# apollo3c register map
Vendor: Ambiq Micro; Series: Apollo; File version: 1.0
CPU: CM4 r1p0, little endian, MPU, FPU, 3 interrupt priority bits
Registers are 32-bit, read-write, reset 0x0 unless marked. A register's access mark holds for its fields unless they carry their own. Offsets are from the block's base; [hi:lo] are bit positions; {n}, {i} and the like mark numbered series; 'fields as' and 'values as' point back to an identical list.

## IOM0 — IO Peripheral Master
Base 0x50004000
Same registers: IOM1 0x50005000, IOM2 0x50006000, IOM3 0x50007000, IOM4 0x50008000, IOM5 0x50009000
0x00 FIFO — FIFO Access Port
  [31:0] FIFO — FIFO direct access. Only locations 0 - 3F will return valid information.
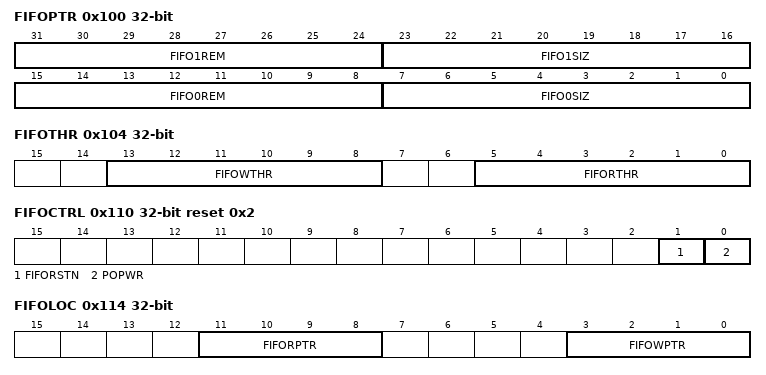
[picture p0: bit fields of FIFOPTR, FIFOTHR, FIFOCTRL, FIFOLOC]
0x100 FIFOPTR — FIFO size and remaining slots open values
  [31:24] FIFO1REM — The number of remaining data bytes slots currently in FIFO 1 (written by interface, read by MCU)
  [23:16] FIFO1SIZ — The number of valid data bytes currently in FIFO 1 (written by interface, read by MCU)
  [15:8] FIFO0REM — The number of remaining data bytes slots currently in FIFO 0 (written by MCU, read by interface)
  [7:0] FIFO0SIZ — The number of valid data bytes currently in the FIFO 0 (written by MCU, read by interface)
0x104 FIFOTHR — FIFO Threshold Configuration
  [13:8] FIFOWTHR — FIFO write threshold in bytes. A value of 0 will disable the write FIFO level from activating the threshold interrupt. If this field is non-zero, it will trigger a threshold interrupt when the write fifo contains FIFOWTHR free bytes, as indicated by the FIFO0REM field. This is intended to signal when a transfer of FIFOWTHR bytes can be done from the host to the IOM write fifo to support large IOM write operations.
  [5:0] FIFORTHR — FIFO read threshold in bytes. A value of 0 will disable the read FIFO level from activating the threshold interrupt. If this field is non-zero, it will trigger a threshold interrupt when the read fifo contains FIFORTHR valid bytes of data, as indicated by the FIFO1SIZ field. This is intended to signal when a data transfer of FIFORTHR bytes can be done from the IOM module to the host via the read fifo to support large IOM read operations.
0x108 FIFOPOP
  [31:0] FIFODOUT — This register will return the read data indicated by the current read pointer on reads. If the POPWR control bit in the FIFOCTRL register is reset (0), the fifo read pointer will be advanced by one word as a result of the read. If the POPWR bit is set (1), the fifo read pointer will only be advanced after a write operation to this register. The write data is ignored for this register. If less than a even word multiple is available, and the command is completed, the module will return the word containing these bytes and undetermined data in the unused fields of the word.
0x10C FIFOPUSH
  [31:0] FIFODIN — This register is used to write the FIFORAM in FIFO mode and will cause a push event to occur to the next open slot within the FIFORAM. Writing to this register will cause the write point to increment by 1 word(4 bytes).
0x110 FIFOCTRL reset 0x2 — FIFO Control Register
  [1] FIFORSTN — Active low manual reset of the fifo. Write to 0 to reset fifo, and then write to 1 to remove the reset.
  [0] POPWR — Selects the mode in which 'pop' events are done for the fifo read operations. A value of '1' will prevent a pop event on a read operation, and will require a write to the FIFOPOP register to create a pop event. A value of '0' in this register will allow a pop event to occur on the read of the FIFOPOP register, and may cause inadvertant fifo pops when used in a debugging mode.
0x114 FIFOLOC — FIFO Pointers
  [11:8] FIFORPTR — Current FIFO read pointer. Used to index into the incoming FIFO (FIFO1), which is used to store read data returned from external devices during a read operation.
  [3:0] FIFOWPTR — Current FIFO write pointer. Value is the index into the outgoing FIFO (FIFO0), which is used during write operations to external devices.
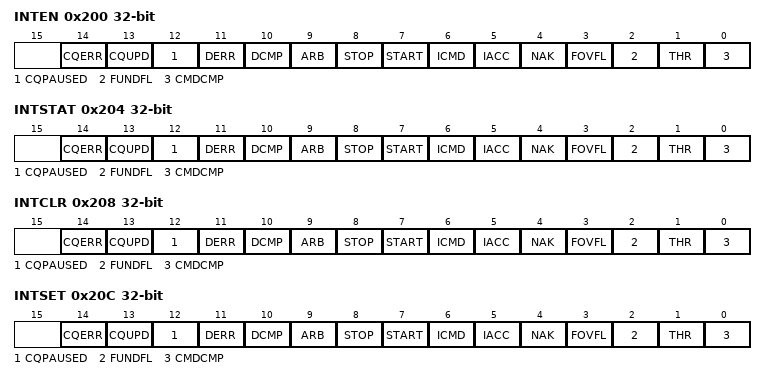
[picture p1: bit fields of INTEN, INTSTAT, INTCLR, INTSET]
0x200 INTEN — IO Master Interrupts: Enable
  [14] CQERR — Error during command queue operations
  [13] CQUPD — CQ write operation performed a register write with the register address bit 0 set to 1. The low address bits in the CQ address fields are unused and bit 0 can be used to trigger an interrupt to indicate when this register write is performed by the CQ operation.
  [12] CQPAUSED — Command queue is paused due to an active event enabled in the PAUSEEN register. The interrupt is posted when the event is enabled within the PAUSEEN register, the mask is active in the CQIRQMASK field and the event occurs.
  [11] DERR — DMA Error encountered during the processing of the DMA command. The DMA error could occur when the memory access specified in the DMA operation is not available or incorrectly specified.
  [10] DCMP — DMA Complete. Processing of the DMA operation has completed and the DMA submodule is returned into the idle state
  [9] ARB — Arbitration loss interrupt. Asserted when arbitration is enabled and has been lost to another master on the bus.
  [8] STOP — STOP command interrupt. Asserted when another master on the bus has signaled a STOP command.
  [7] START — START command interrupt. Asserted when another master on the bus has signaled a START command.
  [6] ICMD — illegal command interrupt. Asserted when a command is written when an active command is in progress.
  [5] IACC — illegal FIFO access interrupt. Asserted when there is a overflow or underflow event
  [4] NAK — I2C NAK interrupt. Asserted when an unexpected NAK has been received on the I2C bus.
  [3] FOVFL — Write FIFO Overflow interrupt. This occurs when software tries to write to a full fifo. The current operation does not stop.
  [2] FUNDFL — Read FIFO Underflow interrupt. This occurs when software tries to pop from an empty fifo.
  [1] THR — FIFO Threshold interrupt. For write operations, asserted when the number of free bytes in the write FIFO equals or exceeds the WTHR field. For read operations, asserted when the number of valid bytes in the read FIFO equals of exceeds the value set in the RTHR field.
  [0] CMDCMP — Command complete interrupt
0x204 INTSTAT — IO Master Interrupts: Status
  fields as INTEN
0x208 INTCLR — IO Master Interrupts: Clear
  fields as INTEN
0x20C INTSET — IO Master Interrupts: Set
  fields as INTEN
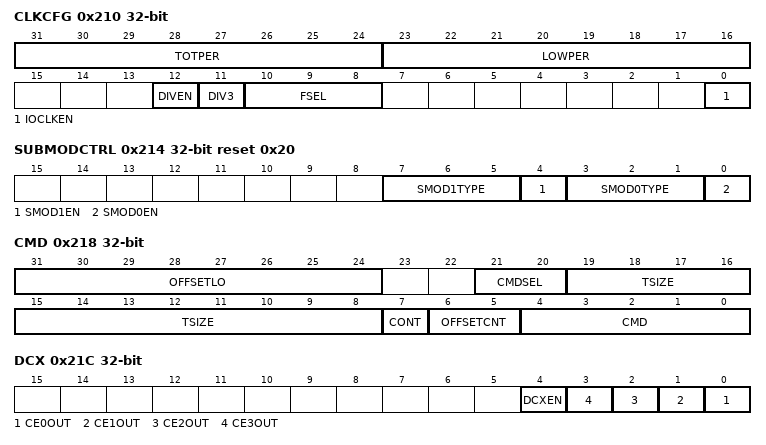
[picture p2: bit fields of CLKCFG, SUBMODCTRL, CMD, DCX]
0x210 CLKCFG — I/O Clock Configuration
  [31:24] TOTPER — Clock total clock count minus 1. This provides the total period of the divided clock -1 when the DIVEN is active. The source clock is selected by FSEL. Only applicable when DIVEN = 1.
  [23:16] LOWPER — Clock low clock count minus 1. This provides the number of clocks the divided clock will be low when the DIVEN = 1. Only applicable when DIVEN = 1.
  [12] DIVEN — Enable clock division by TOTPER and LOWPER
    0=DIS (Disable TOTPER division.); 1=EN (Enable TOTPER division.)
  [11] DIV3 — Enable divide by 3 of the source IOCLK. Division by 3 is done before the DIVEN programmable divider, and if enabled will provide the divided by 3 clock as the source to the programmable divider.
    0=DIS (Select divide by 1.); 1=EN (Select divide by 3.)
  [10:8] FSEL — Select the input clock frequency.
    0=MIN_PWR (Selects the minimum power clock. This setting should be used whenever the IOM is not active.); 1=HFRC (Selects the HFRC as the input clock.); 2=HFRC_DIV2 (Selects the HFRC / 2 as the input clock.); 3=HFRC_DIV4 (Selects the HFRC / 4 as the input clock.); 4=HFRC_DIV8 (Selects the HFRC / 8 as the input clock.); 5=HFRC_DIV16 (Selects the HFRC / 16 as the input clock.); 6=HFRC_DIV32 (Selects the HFRC / 32 as the input clock.); 7=HFRC_DIV64 (Selects the HFRC / 64 as the input clock.)
  [0] IOCLKEN — Enable for the interface clock. Must be enabled prior to executing any IO operations.
0x214 SUBMODCTRL reset 0x20 — Submodule control
  [7:5] SMOD1TYPE — Submodule 0 module type. This is the I2C Master interface
    0=MSPI (SPI Master submodule); 1=I2C_MASTER (MI2C submodule); 2=SSPI (SPI Slave submodule); 3=SI2C (I2C Slave submodule); 7=NA (NOT INSTALLED)
  [4] SMOD1EN — Submodule 1 enable (1) or disable (0)
  [3:1] SMOD0TYPE — Submodule 0 module type. This is the SPI Master interface.
    0=SPI_MASTER (MSPI submodule); 1=I2C_MASTER (I2C Master submodule); 2=SSPI (SPI Slave submodule); 3=SI2C (I2C Slave submodule); 7=NA (NOT INSTALLED)
  [0] SMOD0EN — Submodule 0 enable (1) or disable (0)
0x218 CMD — Command and offset Register
  [31:24] OFFSETLO — This register holds the low order byte of offset to be used in the transaction. The number of offset bytes to use is set with bits 1:0 of the command.
  [21:20] CMDSEL — Command Specific selection information. Not used in Master I2C. Used as CEn select for Master SPI transactions
  [19:8] TSIZE — Defines the transaction size in bytes. The offset transfer is not included in this size.
  [7] CONT — Contine to hold the bus after the current transaction if set to a 1 with a new command issued.
  [6:5] OFFSETCNT — Number of offset bytes to use for the command - 0, 1, 2, 3 are valid selections. The second (byte 1) and third byte (byte 2) are read from the OFFSETHI register, and the low order byte is pulled from this register in the OFFSETLO field. Offset bytes are transmitted highest byte first. EG if offsetcnt == 3, OFFSETHI[15:8] will be transmitted first, then OFFSETHI[7:0] then OFFSETLO. If offsetcnt == 2, OFFSETHI[7:0] will be transmitted, then OFFSETLO. If offsetcnt == 1, only OFFSETLO will be transmitted. Offset bytes are always transmitted MSB first, regardless of the value of the LSB control bit within the module configuration.
  [4:0] CMD — Command for submodule.
    1=WRITE (Write command using count of offset bytes specified in the OFFSETCNT field); 2=READ (Read command using count of offset bytes specified in the OFFSETCNT field); 3=TMW (SPI only. Test mode to do constant write operations. Useful for debug and power measurements. Will continually send data in OFFSET field); 4=TMR (SPI Only. Test mode to do constant read operations. Useful for debug and power measurements. Will continually read data from external input)
0x21C DCX — DCX Control Register
  [4] DCXEN — DCX Signaling Enable The selected DCX signal (unused CE pin) will be driven low during write of offset byte, and high during transmission of data bytes.
    16=EN (Enable DCX.); 0=DIS (Disable DCX.)
  [n] CE{n}OUT (n=0..3) — Enable DCX output using CE{n} output
0x220 OFFSETHI — High order 2 bytes of 3 byte offset for IO transaction
  [15:0] OFFSETHI — Holds the high order 2 bytes of the 3 byte addressing/offset field to use with IO commands. The number of offset bytes to use is specified in the command register
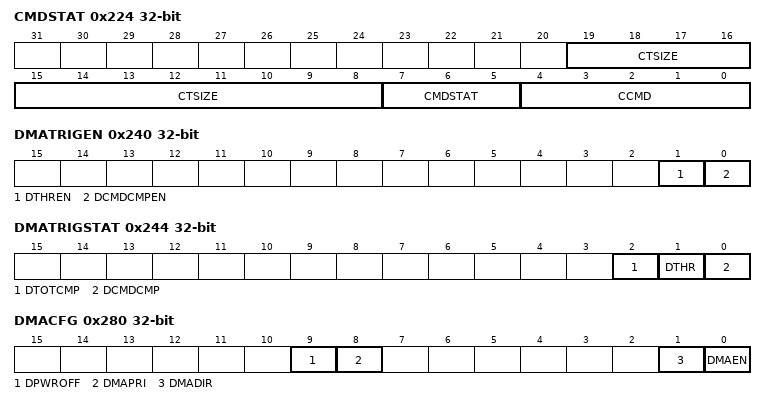
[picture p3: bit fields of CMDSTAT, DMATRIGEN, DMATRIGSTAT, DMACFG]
0x224 CMDSTAT — Command status
  [19:8] CTSIZE — The current number of bytes still to be transferred with this command. This field will count down to zero.
  [7:5] CMDSTAT — The current status of the command execution.
    1=ERR (Error encountered with command); 2=ACTIVE (Actively processing command); 4=IDLE (Idle state, no active command, no error); 6=WAIT (Command in progress, but waiting on data from host)
  [4:0] CCMD — current command that is being executed
0x240 DMATRIGEN — DMA Trigger Enable Register
  [1] DTHREN — Trigger DMA upon THR level reached. For M2P DMA operations (IOM writes), the trigger will assert when the write FIFO has (WTHR/4) number of words free in the write FIFO, and will transfer (WTHR/4) number of words or, if the number of words left to transfer is less than the WTHR value, will transfer the remaining byte count. For P2M DMA operations, the trigger will assert when the read FIFO has (RTHR/4) words available in the read FIFO, and will transfer (RTHR/4) words to SRAM. This trigger will NOT assert when the transaction completes and there are less than RTHR bytes left in the fifo, since the RTHR has not been reached. In this case, the CMDCMP trigger must also be enabled to transfer the remaining read FIFO data to SRAM.
  [0] DCMDCMPEN — Trigger DMA upon command complete. Enables the trigger of the DMA when a command is completed. When this event is triggered, the number of words transferred will be the lesser of the remaining TOTCOUNT bytes, or
0x244 DMATRIGSTAT — DMA Trigger Status Register
  [2] DTOTCMP — DMA triggered when DCMDCMP = 0, and the amount of data in the FIFO was enough to complete the DMA operation (greater than or equal to current TOTCOUNT) when the command completed. This trigger is default active when the DCMDCMP trigger is disabled and there is enough data in the FIFO to complete the DMA operation.
  [1] DTHR — Triggered DMA from THR event. Bit is read only and can be cleared by disabling the DTHR trigger enable or by disabling DMA.
  [0] DCMDCMP — Triggered DMA from Command complete event. Bit is read only and can be cleared by disabling the DCMDCMP trigger enable or by disabling DMA.
0x280 DMACFG — DMA Configuration Register
  [9] DPWROFF — Power off module after DMA is complete. If this bit is active, the module will request to power off the supply it is attached to. If there are other units still requiring power from the same domain, power down will not be performed.
    0=DIS (Power off disabled); 1=EN (Power off enabled)
  [8] DMAPRI — Sets the Priority of the DMA request
    0=LOW (Low Priority (service as best effort)); 1=HIGH (High Priority (service immediately))
  [1] DMADIR — Direction
    0=P2M (Peripheral to Memory (SRAM) transaction. To be set when doing IOM read operations, ie reading data from external devices.); 1=M2P (Memory to Peripheral transaction. To be set when doing IOM write operations, ie writing data to external devices.)
  [0] DMAEN — DMA Enable. Setting this bit to EN will start the DMA operation. This should be the last DMA related register set prior to issuing the command
    0=DIS (Disable DMA Function); 1=EN (Enable DMA Function)
0x288 DMATOTCOUNT — DMA Total Transfer Count
  [11:0] TOTCOUNT — Triggered DMA from Command complete event occured. Bit is read only and can be cleared by disabling the DTHR trigger enable or by disabling DMA.
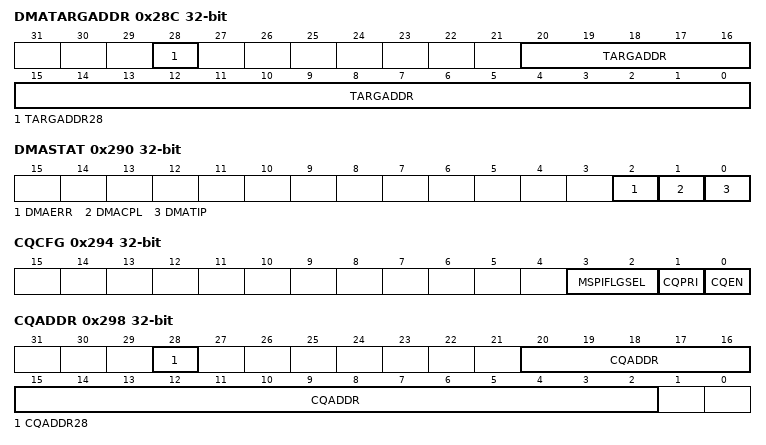
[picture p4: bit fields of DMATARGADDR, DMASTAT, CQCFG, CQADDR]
0x28C DMATARGADDR — DMA Target Address Register
  [28] TARGADDR28 — Bit 28 of the target byte address for source of DMA (either read or write). In cases of non-word aligned addresses, the DMA logic will take care for ensuring only the target bytes are read/written. Setting to '1' will select the SRAM. Setting to '0' will select the flash
  [20:0] TARGADDR — Bits [19:0] of the target byte address for source of DMA (either read or write). The address can be any byte alignment, and does not have to be word aligned. In cases of non-word aligned addresses, the DMA logic will take care for ensuring only the target bytes are read/written.
0x290 DMASTAT — DMA Status Register
  [2] DMAERR — DMA Error. This active high bit signals an error was encountered during the DMA operation. The bit can be cleared by writing to 0. Once set, this bit will remain set until cleared by software.
  [1] DMACPL — DMA Transfer Complete. This signals the end of the DMA operation. This bit can be cleared by writing to 0, and will also be cleared when a new DMA is started.
  [0] DMATIP — DMA Transfer In Progress indicator. 1 will indicate that a DMA transfer is active. The DMA transfer may be waiting on data, transferring data, or waiting for priority. All of these will be indicated with a 1. A 0 will indicate that the DMA is fully complete and no further transactions will be done. This bit is read only.
0x294 CQCFG — Command Queue Configuration Register
  [3:2] MSPIFLGSEL — Selects the MPSI modules used for sourcing the CQFLAG [11:8].
    0=MSPI0FLGSEL (Selects MPSI0 as source of signals used in CGFLAG[11:8].); 1=MSPI1FLGSEL (Selects MPSI1 as source of signals used in CGFLAG[11:8].); 2=MSPI2FLGSEL (Selects MPSI2 as source of signals used in CGFLAG[11:8].)
  [1] CQPRI — Sets the Priority of the command queue dma request
    values as DMACFG.DMAPRI
  [0] CQEN — Command queue enable. When set, will enable the processing of the command queue and fetches of address/data pairs will proceed from the word address within the CQADDR register. Can be disabled using a CQ executed write to this bit as well.
    0=DIS (Disable CQ Function); 1=EN (Enable CQ Function)
0x298 CQADDR — CQ Target Read Address Register
  [28] CQADDR28 — Bit 28 of target byte address for source of CQ. Used to denote Flash (0) or SRAM (1) access
  [20:2] CQADDR — Bits 19:2 of target byte address for source of CQ. The buffer must be aligned on a word boundary
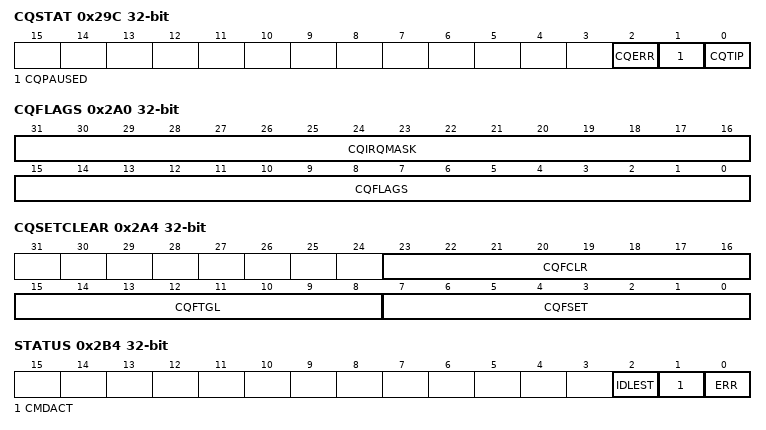
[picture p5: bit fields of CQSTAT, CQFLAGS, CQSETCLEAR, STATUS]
0x29C CQSTAT — Command Queue Status Register
  [2] CQERR — Command queue processing Error. This active high bit signals that an error was encountered during the CQ operation.
  [1] CQPAUSED — Command queue operation is currently paused.
  [0] CQTIP — Command queue Transfer In Progress indicator. 1 will indicate that a CQ transfer is active and this will remain active even when paused waiting for external event.
0x2A0 CQFLAGS — Command Queue Flag Register
  [31:16] CQIRQMASK — Mask the bits used to generate the command queue interrupt. A '1' in the bit position will enable the pause event to trigger the interrupt, if the CQWT_int interrupt is enabled. Bits definitions are the same as CQPAUSE
  [15:0] CQFLAGS — Current flag status (read-only). Bits [7:0] are software controllable and bits [15:8] are hardware status.
0x2A4 CQSETCLEAR — Command Queue Flag Set/Clear Register
  [23:16] CQFCLR — Clear CQFlag status bits. Will clear to 0 any SWFLAG with a '1' in the corresponding bit position of this field
  [15:8] CQFTGL — Toggle the indicated bit. Will toggle the value of any SWFLAG with a '1' in the corresponding bit position of this field
  [7:0] CQFSET — Set CQFlag status bits. Will set to 1 the value of any SWFLAG with a '1' in the corresponding bit position of this field
0x2A8 CQPAUSEEN — Command Queue Pause Enable Register
  [15:0] CQPEN — Enables the specified event to pause command processing when active
    0x8000=IDXEQ (Pauses the command queue when the current index matches the last index); 0x4000=BLEXOREN (Pause command queue when input BLE bit XORed with SWFLAG4 is '1'); 0x2000=IOMXOREN (Pause command queue when input IOM bit XORed with SWFLAG3 is '1'); 0x1000=GPIOXOREN (Pause command queue when input GPIO irq_bit XORed with SWFLAG2 is '1'); 0x800=MSPI1XNOREN (Pause command queue when selected MSPI input bit 1 (buffer 1 ready) XNORed with SWFLAG1 is '1'. MSPI used is selected in CQCFG.MSPIFLGSEL field.); 0x400=MSPI0XNOREN (Pause command queue when selected MSPI input bit 0 (buffer 0 ready) XNORed with SWFLAG1 is '1'. MSPI used is selected in CQCFG.MSPIFLGSEL field.); 0x200=MSPI1XOREN (Pause command queue when selected MSPI input bit 1 (buffer 1 ready) XORed with SWFLAG1 is '1'. MSPI used is selected in CQCFG.MSPIFLGSEL field.); 0x100=MSPI0XOREN (Pause command queue when selected MSPI input bit 0 (buffer 0 ready) XORed with SWFLAG1 is '1'. MSPI used is selected in CQCFG.MSPIFLGSEL field.); 128=SWFLAGEN7 (Pause the command queue when software flag bit 7 is '1'.); 64=SWFLAGEN6 (Pause the command queue when software flag bit 6 is '1'); 32=SWFLAGEN5 (Pause the command queue when software flag bit 5 is '1'); 16=SWFLAGEN4 (Pause the command queue when software flag bit 4 is '1'); 8=SWFLAGEN3 (Pause the command queue when software flag bit 3 is '1'); 4=SWFLAGEN2 (Pause the command queue when software flag bit 2 is '1'); 2=SWFLAGEN1 (Pause the command queue when software flag bit 1 is '1'); 1=SWFLAGEN0 (Pause the command queue when software flag bit 0 is '1')
0x2AC CQCURIDX — IOM Command Queue current index value . Compared to the CQENDIDX reg contents to generate the IDXEQ Pause event for command queue
  [7:0] CQCURIDX — Holds 8 bits of data that will be compared with the CQENDIX register field. If the values match, the IDXEQ pause event will be activated, which will cause the pausing of command quue operation if the IDXEQ bit is enabled in CQPAUSEEN.
0x2B0 CQENDIDX — IOM Command Queue current index value . Compared to the CQCURIDX reg contents to generate the IDXEQ Pause event for command queue
  [7:0] CQENDIDX — Holds 8 bits of data that will be compared with the CQCURIX register field. If the values match, the IDXEQ pause event will be activated, which will cause the pausing of command quue operation if the IDXEQ bit is enabled in CQPAUSEEN.
0x2B4 STATUS — IOM Module Status Register
  [2] IDLEST — indicates if the active I/O state machine is IDLE. Note - The state machine could be in idle state due to holdoffs from data availability, or as the command gets propagated into the logic from the registers.
    1=IDLE (The I/O state machine is in the idle state.)
  [1] CMDACT — Indicates if the active I/O Command is currently processing a transaction, or command is complete, but the FIFO pointers are still syncronizing internally. This bit will go high at the start of the transaction, and will go low when the command is complete, and the data and pointers within the FIFO have been syncronized.
    1=ACTIVE (An I/O command is active. Indicates the active module has an active command and is processing this. De-asserted when the command is completed.)
  [0] ERR — Bit has been deprecated. Please refer to the other error indicators. This will always return 0.
    1=ERROR (Bit has been deprecated and will always return 0.)
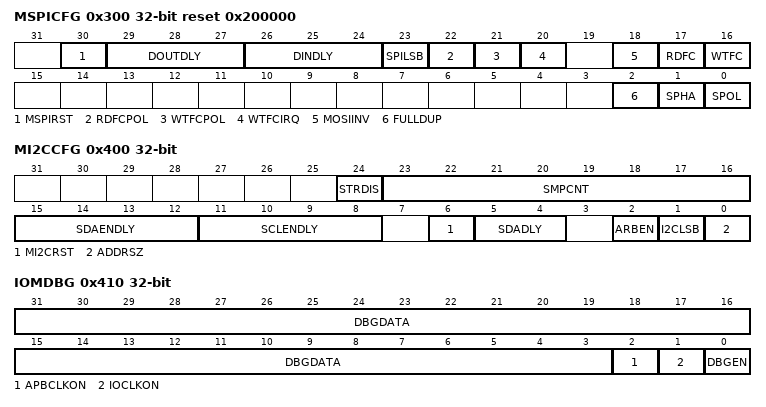
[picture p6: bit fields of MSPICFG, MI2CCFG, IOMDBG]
0x300 MSPICFG reset 0x200000 — SPI module master configuration
  [30] MSPIRST — Not used. To reset the module, toggle the SMOD_EN for the module
  [29:27] DOUTDLY — Delay tap to use for the output signal (MOSI). This give more hold time on the output data
  [26:24] DINDLY — Delay tap to use for the input signal (MISO). This gives more hold time on the input data.
  [23] SPILSB — Selects data transfer as MSB first (0) or LSB first (1) for the data portion of the SPI transaction. The offset bytes are always transmitted MSB first.
    0=MSB (Send and receive MSB bit first); 1=LSB (Send and receive LSB bit first)
  [22] RDFCPOL — selects the read flow control signal polarity.
    0=HIGH (Flow control signal high creates flow control.); 1=LOW (Flow control signal low creates flow control.)
  [21] WTFCPOL — selects the write flow control signal polarity. The transfers are halted when the selected flow control signal is OPPOSITE polarity of bit. (For example: WTFCPOL = 0 will allow a IRQ=1 to pause transfers).
    0=HIGH (Flow control signal high(1) creates flow control and byte transfers will stop until the flow control signal goes low.); 1=LOW (Flow control signal low(0) creates flow control and byte transfers will stop until the flow control signal goes high(1).)
  [20] WTFCIRQ — selects the write mode flow control signal.
    0=MISO (MISO is used as the write mode flow control signal.); 1=IRQ (IRQ is used as the write mode flow control signal.)
  [18] MOSIINV — inverts MOSI when flow control is enabled.
    0=NORMAL (MOSI is set to 0 in read mode and 1 in write mode.); 1=INVERT (MOSI is set to 1 in read mode and 0 in write mode.)
  [17] RDFC — enables read mode flow control.
    0=DIS (Read mode flow control disabled.); 1=EN (Read mode flow control enabled.)
  [16] WTFC — enables write mode flow control.
    0=DIS (Write mode flow control disabled.); 1=EN (Write mode flow control enabled.)
  [2] FULLDUP — Enables full duplex mode for Master SPI write operations. Data will be captured simultaneously into the read fifo
  [1] SPHA — selects SPI phase.
    0=SAMPLE_LEADING_EDGE (Sample on the leading (first) clock edge.); 1=SAMPLE_TRAILING_EDGE (Sample on the trailing (second) clock edge.)
  [0] SPOL — selects SPI polarity.
    0=CLK_BASE_0 (The base value of the clock is 0.); 1=CLK_BASE_1 (The base value of the clock is 1.)
0x400 MI2CCFG — I2C Master configuration
  [24] STRDIS — Disable detection of clock stretch events smaller than 1 cycle
  [23:16] SMPCNT — Number of Base clk cycles to wait before sampling the SCL clock to determine if a clock stretch event has occured
  [15:12] SDAENDLY — Number of IOCLK cycles to delay the SDA output en (all transitions affected). Used to delay data relative to clock
  [11:8] SCLENDLY — Number of IOCLK cycles to delay the rising edge of the SCL output en (clock will go low on this edge). Used to allow clock shaping.
  [6] MI2CRST — Not used. To reset the module, toggle the SMOD_EN for the module
  [5:4] SDADLY — Delay to enable on the SDA output. Values are 0x0-0x3.
  [2] ARBEN — Enables multi-master arbitration for the I2C master. If the bus is known to have only a single master, this function can be disabled to save clock cycles on I2C transactions
    1=ARBEN (Enable multi-master bus arbitration support for this i2c master); 0=ARBDIS (Disable multi-master bus arbitration support for this i2c master)
  [1] I2CLSB — Direction of data transmit and receive, MSB(0) or LSB(1) first. Default per I2C specification is MSB first. This applies to both read and write data, and read data will be bit
    0=MSBFIRST (Byte data is transmitted MSB first onto the bus/read from the bus); 1=LSBFIRST (Byte data is transmitted LSB first onto the bus/read from the bus)
  [0] ADDRSZ — Sets the I2C master device address size to either 7b (0) or 10b (1).
    0=Use 7b addressing for I2C master transactions; 1=Use 10b addressing for I2C master transactions
0x404 DEVCFG — I2C Device Configuration register
  [9:0] DEVADDR — I2C address of the device that the Master will use to target for read/write operations. This can be either a 7b or 10b address.
0x410 IOMDBG — IOM Debug Register
  [31:3] DBGDATA — Debug control for various options. DBGDATA[1:0] is used to select between different debug data available in the DBG0 and DBG1 registers.
  [2] APBCLKON — APBCLK debug clock control. Enable APB_CLK to be active when this bit is '1'. Otherwise, the clock is controlled with gating from the logic as needed.
  [1] IOCLKON — IOCLK debug clock control. Enable IO_CLK to be active when this bit is '1'. Otherwise, the clock is controlled with gating from the logic as needed.
  [0] DBGEN — Debug Enable. Setting bit will enable the update of data within this register, otherwise it is clock gated for power savings
